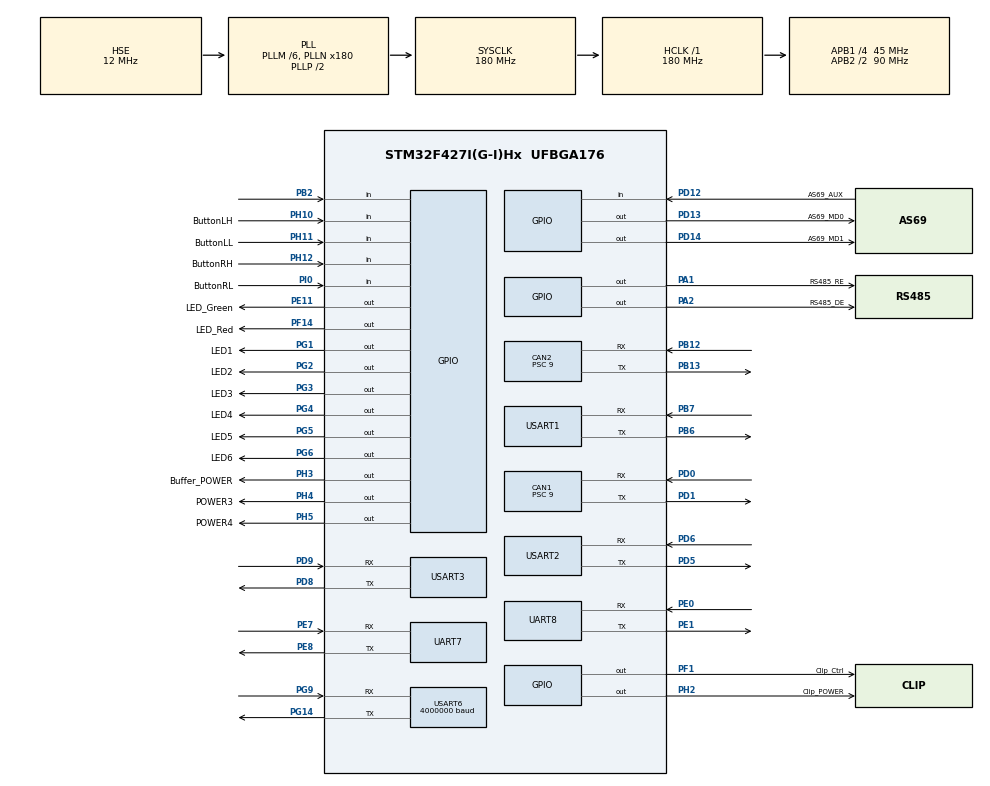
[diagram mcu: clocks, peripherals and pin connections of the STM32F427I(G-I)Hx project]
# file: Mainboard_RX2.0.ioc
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CAN1.BS1=CAN_BS1_3TQ
CAN1.CalculateBaudRate=1000000
CAN1.CalculateTimeBit=1000
CAN1.CalculateTimeQuantum=200.0
CAN1.Prescaler=9
CAN2.BS1=CAN_BS1_3TQ
CAN2.CalculateBaudRate=1000000
CAN2.CalculateTimeBit=1000
CAN2.CalculateTimeQuantum=200.0
CAN2.Prescaler=9
Dma.Request0=USART6_RX
Dma.Request1=USART2_TX
Dma.USART2_TX.1.Direction=DMA_MEMORY_TO_PERIPH
Dma.USART2_TX.1.FIFOMode=DMA_FIFOMODE_DISABLE
Dma.USART2_TX.1.Instance=DMA1_Stream6
Dma.USART2_TX.1.MemDataAlignment=DMA_MDATAALIGN_BYTE
Dma.USART2_TX.1.MemInc=DMA_MINC_ENABLE
Dma.USART2_TX.1.Mode=DMA_NORMAL
Dma.USART2_TX.1.PeriphDataAlignment=DMA_PDATAALIGN_BYTE
Dma.USART2_TX.1.PeriphInc=DMA_PINC_DISABLE
Dma.USART2_TX.1.Priority=DMA_PRIORITY_LOW
Dma.USART6_RX.0.Direction=DMA_PERIPH_TO_MEMORY
Dma.USART6_RX.0.FIFOMode=DMA_FIFOMODE_DISABLE
Dma.USART6_RX.0.Instance=DMA2_Stream2
Dma.USART6_RX.0.MemDataAlignment=DMA_MDATAALIGN_BYTE
Dma.USART6_RX.0.MemInc=DMA_MINC_ENABLE
Dma.USART6_RX.0.Mode=DMA_NORMAL
Dma.USART6_RX.0.PeriphDataAlignment=DMA_PDATAALIGN_BYTE
Dma.USART6_RX.0.PeriphInc=DMA_PINC_DISABLE
Dma.USART6_RX.0.Priority=DMA_PRIORITY_HIGH
FREERTOS.Tasks01=defaultTask,24,2048,StartDefaultTask,As weak,NULL,Dynamic,NULL,NULL
FREERTOS.configENABLE_FPU=1
FREERTOS.configTOTAL_HEAP_SIZE=150000
Mcu.Family=STM32F4
Mcu.Name=STM32F427I(G-I)Hx
Mcu.Package=UFBGA176
NVIC.CAN1_RX0_IRQn=true\:5\:0\:false\:false\:true\:true\:true\:true\:true
NVIC.CAN2_RX0_IRQn=true\:5\:0\:false\:false\:true\:true\:true\:true\:true
NVIC.CAN2_RX1_IRQn=true\:5\:0\:false\:false\:true\:true\:true\:true\:true
NVIC.DMA1_Stream6_IRQn=true\:5\:0\:false\:false\:true\:true\:false\:true\:true
NVIC.DMA2_Stream2_IRQn=true\:5\:0\:false\:false\:true\:true\:false\:true\:true
NVIC.PriorityGroup=NVIC_PRIORITYGROUP_4
NVIC.TIM1_UP_TIM10_IRQn=true\:15\:0\:false\:false\:true\:false\:false\:true\:true
NVIC.TIM3_IRQn=true\:5\:0\:false\:false\:true\:true\:true\:true\:true
NVIC.TimeBase=TIM1_UP_TIM10_IRQn
NVIC.TimeBaseIP=TIM1
NVIC.UART7_IRQn=true\:5\:0\:false\:false\:true\:true\:true\:true\:true
NVIC.UART8_IRQn=true\:5\:0\:false\:false\:true\:true\:true\:true\:true
NVIC.USART2_IRQn=true\:5\:0\:false\:false\:true\:true\:true\:true\:true
NVIC.USART3_IRQn=true\:5\:0\:false\:false\:true\:true\:true\:true\:true
NVIC.USART6_IRQn=true\:5\:0\:false\:false\:true\:true\:true\:true\:true
PA1.GPIO_Label=RS485_RE
PA1.GPIO_Speed=GPIO_SPEED_FREQ_VERY_HIGH
PA1.Signal=GPIO_Output
PA13.Mode=Serial_Wire
PA13.Signal=SYS_JTMS-SWDIO
PA14.Mode=Serial_Wire
PA14.Signal=SYS_JTCK-SWCLK
PA2.GPIO_Label=RS485_DE
PA2.GPIO_Speed=GPIO_SPEED_FREQ_VERY_HIGH
PA2.Signal=GPIO_Output
PB12.Mode=CAN_Activate
PB12.Signal=CAN2_RX
PB13.Mode=CAN_Activate
PB13.Signal=CAN2_TX
PB2/BOOT1.Signal=GPIO_Input
PB6.Mode=Asynchronous
PB6.Signal=USART1_TX
PB7.Mode=Asynchronous
PB7.Signal=USART1_RX
PC14/OSC32_IN.Mode=LSE-External-Oscillator
PC14/OSC32_IN.Signal=RCC_OSC32_IN
PC15/OSC32_OUT.Mode=LSE-External-Oscillator
PC15/OSC32_OUT.Signal=RCC_OSC32_OUT
PD0.Mode=CAN_Activate
PD0.Signal=CAN1_RX
PD1.Mode=CAN_Activate
PD1.Signal=CAN1_TX
PD12.GPIO_Label=AS69_AUX
PD12.GPIO_PuPd=GPIO_PULLUP
PD12.Signal=GPIO_Input
PD13.GPIO_Label=AS69_MD0
PD13.GPIO_PuPd=GPIO_PULLUP
PD13.PinState=GPIO_PIN_SET
PD13.Signal=GPIO_Output
PD14.GPIO_Label=AS69_MD1
PD14.GPIO_PuPd=GPIO_PULLUP
PD14.PinState=GPIO_PIN_SET
PD14.Signal=GPIO_Output
PD5.GPIO_Speed=GPIO_SPEED_FREQ_LOW
PD5.Mode=Asynchronous
PD5.Signal=USART2_TX
PD6.GPIO_Speed=GPIO_SPEED_FREQ_LOW
PD6.Mode=Asynchronous
PD6.Signal=USART2_RX
PD8.GPIO_PuPd=GPIO_NOPULL
PD8.GPIO_Speed=GPIO_SPEED_FREQ_LOW
PD8.Mode=Asynchronous
PD8.Signal=USART3_TX
PD9.GPIO_PuPd=GPIO_NOPULL
PD9.GPIO_Speed=GPIO_SPEED_FREQ_LOW
PD9.Mode=Asynchronous
PD9.Signal=USART3_RX
PE0.GPIO_Speed=GPIO_SPEED_FREQ_LOW
PE0.Mode=Asynchronous
PE0.Signal=UART8_RX
PE1.GPIO_Speed=GPIO_SPEED_FREQ_LOW
PE1.Mode=Asynchronous
PE1.Signal=UART8_TX
PE11.GPIO_Label=LED_Green
PE11.Signal=GPIO_Output
PE7.GPIO_Speed=GPIO_SPEED_FREQ_LOW
PE7.Mode=Asynchronous
PE7.Signal=UART7_RX
PE8.GPIO_Speed=GPIO_SPEED_FREQ_LOW
PE8.Mode=Asynchronous
PE8.Signal=UART7_TX
PF1.GPIO_Label=Clip_Ctrl
PF1.GPIO_Speed=GPIO_SPEED_FREQ_HIGH
PF1.Signal=GPIO_Output
PF14.GPIO_Label=LED_Red
PF14.PinState=GPIO_PIN_SET
PF14.Signal=GPIO_Output
PG1.GPIO_Label=LED1
PG1.Signal=GPIO_Output
PG14.Mode=Asynchronous
PG14.Signal=USART6_TX
PG2.GPIO_Label=LED2
PG2.Signal=GPIO_Output
PG3.GPIO_Label=LED3
PG3.Signal=GPIO_Output
PG4.GPIO_Label=LED4
PG4.Signal=GPIO_Output
PG5.GPIO_Label=LED5
PG5.Signal=GPIO_Output
PG6.GPIO_Label=LED6
PG6.Signal=GPIO_Output
PG9.Mode=Asynchronous
PG9.Signal=USART6_RX
PH0/OSC_IN.Mode=HSE-External-Oscillator
PH0/OSC_IN.Signal=RCC_OSC_IN
PH1/OSC_OUT.Mode=HSE-External-Oscillator
PH1/OSC_OUT.Signal=RCC_OSC_OUT
PH10.GPIO_Label=ButtonLH
PH10.Signal=GPIO_Input
PH11.GPIO_Label=ButtonLL
PH11.Signal=GPIO_Input
PH12.GPIO_Label=ButtonRH
PH12.Signal=GPIO_Input
PH2.GPIO_Label=Clip_POWER
PH2.Signal=GPIO_Output
PH3.GPIO_Label=Buffer_POWER
PH3.Signal=GPIO_Output
PH4.GPIO_Label=POWER3
PH4.Signal=GPIO_Output
PH5.GPIO_Label=POWER4
PH5.Signal=GPIO_Output
PI0.GPIO_Label=ButtonRL
PI0.Signal=GPIO_Input
ProjectManager.HeapSize=0x200
ProjectManager.StackSize=0x400
ProjectManager.TargetToolchain=Makefile
RCC.48MHZClocksFreq_Value=90000000
RCC.AHBFreq_Value=180000000
RCC.APB1CLKDivider=RCC_HCLK_DIV4
RCC.APB1Freq_Value=45000000
RCC.APB1TimFreq_Value=90000000
RCC.APB2CLKDivider=RCC_HCLK_DIV2
RCC.APB2Freq_Value=90000000
RCC.APB2TimFreq_Value=180000000
RCC.CortexFreq_Value=180000000
RCC.HCLKFreq_Value=180000000
RCC.HSE_VALUE=12000000
RCC.HSI_VALUE=16000000
RCC.PLLM=6
RCC.PLLN=180
RCC.PLLSourceVirtual=RCC_PLLSOURCE_HSE
RCC.SYSCLKFreq_VALUE=180000000
RCC.SYSCLKSource=RCC_SYSCLKSOURCE_PLLCLK
RCC.VCOOutputFreq_Value=360000000
STMicroelectronics.X-CUBE-ALGOBUILD.1.4.0.LibraryCcDSPOoLibraryJjDSPOoLibrary=true
STMicroelectronics.X-CUBE-ALGOBUILD.1.4.0.LibraryCcMotionOoLibrariesJjMotionOoLibraries=true
TIM2.Period=1000-1
TIM2.Prescaler=1600-1
TIM3.Period=1000-1
TIM3.Prescaler=900-1
TIM6.Prescaler=180-1
UART7.VirtualMode=Asynchronous
UART8.VirtualMode=Asynchronous
USART1.VirtualMode=VM_ASYNC
USART2.VirtualMode=VM_ASYNC
USART3.VirtualMode=VM_ASYNC
USART6.BaudRate=4000000
USART6.VirtualMode=VM_ASYNC
VP_FREERTOS_VS_CMSIS_V2.Mode=CMSIS_V2
VP_STMicroelectronics.X-CUBE-ALGOBUILD_VS_DSPOoLibraryJjLibrary_1.4.0_1.4.0.Mode=DSPOoLibraryJjLibrary
VP_STMicroelectronics.X-CUBE-ALGOBUILD_VS_MotionOoLibrariesJjLibrary_1.4.0_1.4.0.Mode=MotionOoLibrariesJjLibrary
VP_SYS_VS_tim1.Mode=TIM1
VP_TIM2_VS_ClockSourceINT.Mode=Internal
VP_TIM3_VS_ClockSourceINT.Mode=Internal
VP_TIM6_VS_ClockSourceINT.Mode=Enable_Timer
VP_TIM7_VS_ClockSourceINT.Mode=Enable_Timer
board=custom

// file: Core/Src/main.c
/* USER CODE BEGIN Header */
/**
  ******************************************************************************
  * @file           : main.c
  * @brief          : Main program body
  ******************************************************************************
  * @attention
  *
  * Copyright (c) 2025 STMicroelectronics.
  * All rights reserved.
  *
  * This software is licensed under terms that can be found in the LICENSE file
  * in the root directory of this software component.
  * If no LICENSE file comes with this software, it is provided AS-IS.
  *
  ******************************************************************************
  */
/* USER CODE END Header */
#include "main.h"
#include "cmsis_os.h"
#include "can.h"
#include "dma.h"
#include "tim.h"
#include "usart.h"
#include "gpio.h"

/* USER CODE BEGIN Includes */
#include "usermain.h"
/* USER CODE END Includes */

void SystemClock_Config(void);
void MX_FREERTOS_Init(void);

int main(void)
{

  /* MCU Configuration--------------------------------------------------------*/

  /* Reset of all peripherals, Initializes the Flash interface and the Systick. */
  HAL_Init();

  /* Configure the system clock */
  SystemClock_Config();

  /* Initialize all configured peripherals */
  MX_GPIO_Init();
  MX_DMA_Init();
  MX_CAN1_Init();
  MX_CAN2_Init();
  MX_TIM2_Init();
  MX_UART8_Init();
  MX_USART6_UART_Init();
  MX_USART2_UART_Init();
  MX_UART7_Init();
  MX_TIM6_Init();
  MX_TIM3_Init();
  MX_TIM7_Init();
  MX_USART3_UART_Init();
  MX_USART1_UART_Init();
  /* USER CODE BEGIN 2 */
  //CANFilterInit(&hcan1);
  //ENCODER_CANFilterInit(&hcan2);
  //HAL_CAN_Start(&hcan2);
  //HAL_CAN_ActivateNotification(&hcan2,CAN_IT_RX_FIFO0_MSG_PENDING);
  HAL_TIM_Base_Start_IT(&ENCODER_Calculate_htim);
  /* USER CODE END 2 */

  /* Init scheduler */
  osKernelInitialize();

  /* Call init function for freertos objects (in cmsis_os2.c) */
  MX_FREERTOS_Init();

  /* Start scheduler */
  osKernelStart();

  /* We should never get here as control is now taken by the scheduler */

  /* Infinite loop */
  while (1)
  {

    /* USER CODE BEGIN 3 */
    //HAL_IWDG_Refresh(&hiwdg);
  }
  /* USER CODE END 3 */
}

void SystemClock_Config(void)
{
  RCC_OscInitTypeDef RCC_OscInitStruct = {0};
  RCC_ClkInitTypeDef RCC_ClkInitStruct = {0};

  /** Configure the main internal regulator output voltage
  */
  __HAL_RCC_PWR_CLK_ENABLE();
  __HAL_PWR_VOLTAGESCALING_CONFIG(PWR_REGULATOR_VOLTAGE_SCALE1);

  /** Initializes the RCC Oscillators according to the specified parameters
  * in the RCC_OscInitTypeDef structure.
  */
  RCC_OscInitStruct.OscillatorType = RCC_OSCILLATORTYPE_HSE;
  RCC_OscInitStruct.HSEState = RCC_HSE_ON;
  RCC_OscInitStruct.PLL.PLLState = RCC_PLL_ON;
  RCC_OscInitStruct.PLL.PLLSource = RCC_PLLSOURCE_HSE;
  RCC_OscInitStruct.PLL.PLLM = 6;
  RCC_OscInitStruct.PLL.PLLN = 180;
  RCC_OscInitStruct.PLL.PLLP = RCC_PLLP_DIV2;
  RCC_OscInitStruct.PLL.PLLQ = 4;
  if (HAL_RCC_OscConfig(&RCC_OscInitStruct) != HAL_OK)
  {
    Error_Handler();
  }

  /** Activate the Over-Drive mode
  */
  if (HAL_PWREx_EnableOverDrive() != HAL_OK)
  {
    Error_Handler();
  }

  /** Initializes the CPU, AHB and APB buses clocks
  */
  RCC_ClkInitStruct.ClockType = RCC_CLOCKTYPE_HCLK|RCC_CLOCKTYPE_SYSCLK
                              |RCC_CLOCKTYPE_PCLK1|RCC_CLOCKTYPE_PCLK2;
  RCC_ClkInitStruct.SYSCLKSource = RCC_SYSCLKSOURCE_PLLCLK;
  RCC_ClkInitStruct.AHBCLKDivider = RCC_SYSCLK_DIV1;
  RCC_ClkInitStruct.APB1CLKDivider = RCC_HCLK_DIV4;
  RCC_ClkInitStruct.APB2CLKDivider = RCC_HCLK_DIV2;

  if (HAL_RCC_ClockConfig(&RCC_ClkInitStruct, FLASH_LATENCY_5) != HAL_OK)
  {
    Error_Handler();
  }
}

void HAL_TIM_PeriodElapsedCallback(TIM_HandleTypeDef *htim)
{
  if (htim->Instance == TIM1)
  {
    HAL_IncTick();
  }
  /* USER CODE BEGIN Callback 1 */

  //码盘速度计算定时器回调
  /*if(htim->Instance == OPS_Calculate_TIM)
  {
      my_Chassis_Odom_v.current_pos[0] = OPS_Data.pos_x;
      my_Chassis_Odom_v.current_pos[1] = OPS_Data.pos_y;
      my_Chassis_Odom_v.current_v[0] = (my_Chassis_Odom_v.current_pos[0] - my_Chassis_Odom_v.last_pos[0])/OPS_Calculate_Time;
      my_Chassis_Odom_v.current_v[1] = (my_Chassis_Odom_v.current_pos[1] - my_Chassis_Odom_v.last_pos[1])/OPS_Calculate_Time;
      my_Chassis_Odom_v.last_pos[0]  = my_Chassis_Odom_v.current_pos[0];
      my_Chassis_Odom_v.last_pos[1]  = my_Chassis_Odom_v.current_pos[1];

      //雷达位置微分速度
      my_Alldir_Chassis_t.last_pos.xpos = my_Alldir_Chassis_t.current_pos.xpos;
      my_Alldir_Chassis_t.last_pos.ypos = my_Alldir_Chassis_t.current_pos.ypos;

      my_Alldir_Chassis_t.current_pos.xpos = Lidar_pose[0];
      my_Alldir_Chassis_t.current_pos.ypos = Lidar_pose[1];

      my_Alldir_Chassis_t.current_v.vx = (my_Alldir_Chassis_t.current_pos.xpos - my_Alldir_Chassis_t.last_pos.xpos)/OPS_Calculate_Time;
      my_Alldir_Chassis_t.current_v.vy = (my_Alldir_Chassis_t.current_pos.ypos - my_Alldir_Chassis_t.last_pos.ypos)/OPS_Calculate_Time;
  }*/

  // //角编码器角速度计算
  // if(htim->Instance == ENCODER_Calculate_TIM)
  // {
  //     encoderData.encoder_W = (encoderData.angle - encoderData.last_angle)/ENCODER_Calculate_Time;
  //     encoderData.last_angle = encoderData.angle;
  // }
  /* USER CODE END Callback 1 */
}

void Error_Handler(void)
{
  __disable_irq();
  while (1)
  {
  }
}

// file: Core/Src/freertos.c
/* USER CODE BEGIN Header */
/**
  ******************************************************************************
  * File Name          : freertos.c
  * Description        : Code for freertos applications
  ******************************************************************************
  * @attention
  *
  * Copyright (c) 2025 STMicroelectronics.
  * All rights reserved.
  *
  * This software is licensed under terms that can be found in the LICENSE file
  * in the root directory of this software component.
  * If no LICENSE file comes with this software, it is provided AS-IS.
  *
  ******************************************************************************
  */
/* USER CODE END Header */

#include "FreeRTOS.h"
#include "task.h"
#include "main.h"
#include "cmsis_os.h"

/* USER CODE BEGIN Includes */
//#include "iwdg.h"
/* USER CODE END Includes */

/* Definitions for defaultTask */
osThreadId_t defaultTaskHandle;
const osThreadAttr_t defaultTask_attributes = {
  .name = "defaultTask",
  .stack_size = 2048 * 4,
  .priority = (osPriority_t) osPriorityNormal,
};

void StartDefaultTask(void *argument);

void MX_FREERTOS_Init(void); /* (MISRA C 2004 rule 8.1) */

void MX_FREERTOS_Init(void) {

  /* Create the thread(s) */
  /* creation of defaultTask */
  defaultTaskHandle = osThreadNew(StartDefaultTask, NULL, &defaultTask_attributes);

}

__weak void StartDefaultTask(void *argument)
{
  for(;;)
  {
    osDelay(1);
  }
}
